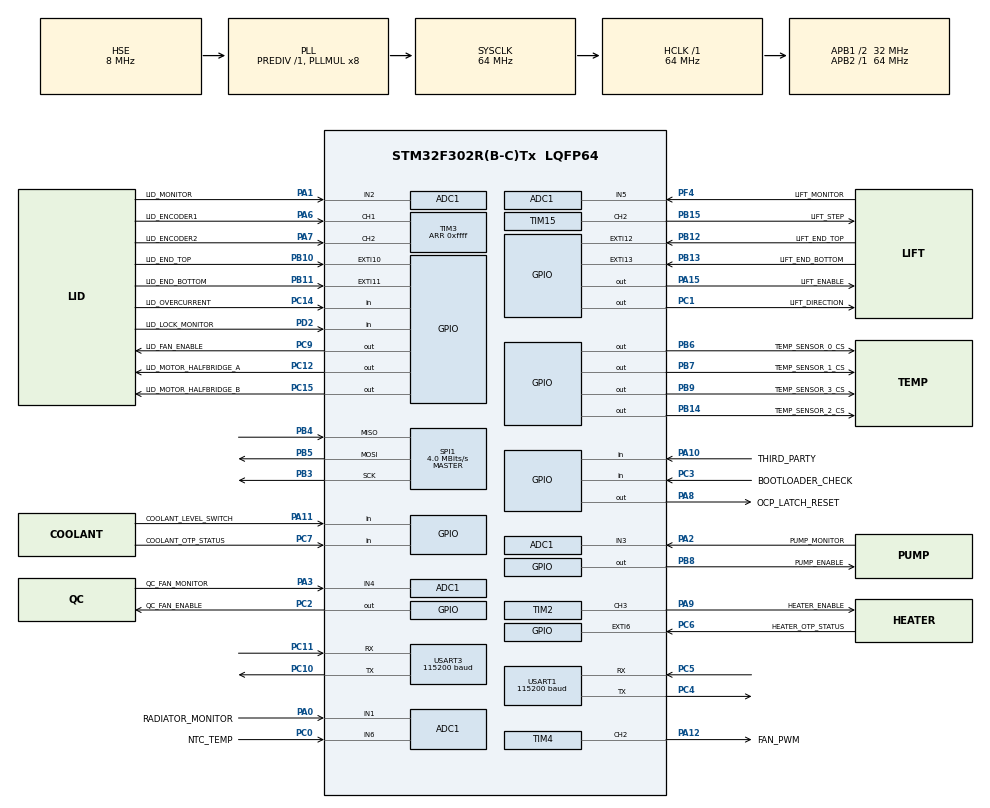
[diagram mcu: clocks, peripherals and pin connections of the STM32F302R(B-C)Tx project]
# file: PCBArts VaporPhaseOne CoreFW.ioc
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ADC1.Channel-0\#ChannelRegularConversion=ADC_CHANNEL_1
ADC1.Channel-1\#ChannelRegularConversion=ADC_CHANNEL_2
ADC1.Channel-2\#ChannelRegularConversion=ADC_CHANNEL_3
ADC1.Channel-3\#ChannelRegularConversion=ADC_CHANNEL_4
ADC1.Channel-4\#ChannelRegularConversion=ADC_CHANNEL_5
ADC1.Channel-5\#ChannelRegularConversion=ADC_CHANNEL_6
ADC1.ContinuousConvMode=ENABLE
ADC1.DMAContinuousRequests=ENABLE
ADC1.NbrOfConversion=6
ADC1.NbrOfConversionFlag=1
ADC1.Offset-0\#ChannelRegularConversion=0
ADC1.Offset-1\#ChannelRegularConversion=0
ADC1.Offset-2\#ChannelRegularConversion=0
ADC1.Offset-3\#ChannelRegularConversion=0
ADC1.Offset-4\#ChannelRegularConversion=0
ADC1.Offset-5\#ChannelRegularConversion=0
ADC1.OffsetNumber-0\#ChannelRegularConversion=ADC_OFFSET_NONE
ADC1.OffsetNumber-1\#ChannelRegularConversion=ADC_OFFSET_NONE
ADC1.OffsetNumber-2\#ChannelRegularConversion=ADC_OFFSET_NONE
ADC1.OffsetNumber-3\#ChannelRegularConversion=ADC_OFFSET_NONE
ADC1.OffsetNumber-4\#ChannelRegularConversion=ADC_OFFSET_NONE
ADC1.OffsetNumber-5\#ChannelRegularConversion=ADC_OFFSET_NONE
ADC1.Rank-0\#ChannelRegularConversion=1
ADC1.Rank-1\#ChannelRegularConversion=2
ADC1.Rank-2\#ChannelRegularConversion=3
ADC1.Rank-3\#ChannelRegularConversion=4
ADC1.Rank-4\#ChannelRegularConversion=5
ADC1.Rank-5\#ChannelRegularConversion=6
ADC1.SamplingTime-0\#ChannelRegularConversion=ADC_SAMPLETIME_601CYCLES_5
ADC1.SamplingTime-1\#ChannelRegularConversion=ADC_SAMPLETIME_601CYCLES_5
ADC1.SamplingTime-2\#ChannelRegularConversion=ADC_SAMPLETIME_601CYCLES_5
ADC1.SamplingTime-3\#ChannelRegularConversion=ADC_SAMPLETIME_601CYCLES_5
ADC1.SamplingTime-4\#ChannelRegularConversion=ADC_SAMPLETIME_601CYCLES_5
ADC1.SamplingTime-5\#ChannelRegularConversion=ADC_SAMPLETIME_601CYCLES_5
ADC1.SamplingTimeOPAMP-1\#ChannelRegularConversion=ADC_SAMPLETIME_61CYCLES_5
ADC1.SamplingTimeOPAMP-2\#ChannelRegularConversion=ADC_SAMPLETIME_61CYCLES_5
ADC1.SamplingTimeOPAMP-3\#ChannelRegularConversion=ADC_SAMPLETIME_61CYCLES_5
ADC1.SamplingTimeOPAMP-4\#ChannelRegularConversion=ADC_SAMPLETIME_61CYCLES_5
ADC1.SamplingTimeOPAMP-5\#ChannelRegularConversion=ADC_SAMPLETIME_61CYCLES_5
ADC1.master=1
Dma.ADC1.4.Direction=DMA_PERIPH_TO_MEMORY
Dma.ADC1.4.Instance=DMA1_Channel1
Dma.ADC1.4.MemDataAlignment=DMA_MDATAALIGN_WORD
Dma.ADC1.4.MemInc=DMA_MINC_ENABLE
Dma.ADC1.4.Mode=DMA_CIRCULAR
Dma.ADC1.4.PeriphDataAlignment=DMA_PDATAALIGN_HALFWORD
Dma.ADC1.4.PeriphInc=DMA_PINC_DISABLE
Dma.ADC1.4.Priority=DMA_PRIORITY_LOW
Dma.Request0=SPI1_RX
Dma.Request1=SPI1_TX
Dma.Request2=USART1_RX
Dma.Request3=USART1_TX
Dma.Request4=ADC1
Dma.SPI1_RX.0.Direction=DMA_PERIPH_TO_MEMORY
Dma.SPI1_RX.0.Instance=DMA1_Channel2
Dma.SPI1_RX.0.MemDataAlignment=DMA_MDATAALIGN_BYTE
Dma.SPI1_RX.0.MemInc=DMA_MINC_ENABLE
Dma.SPI1_RX.0.Mode=DMA_NORMAL
Dma.SPI1_RX.0.PeriphDataAlignment=DMA_PDATAALIGN_BYTE
Dma.SPI1_RX.0.PeriphInc=DMA_PINC_DISABLE
Dma.SPI1_RX.0.Priority=DMA_PRIORITY_HIGH
Dma.SPI1_TX.1.Direction=DMA_MEMORY_TO_PERIPH
Dma.SPI1_TX.1.Instance=DMA1_Channel3
Dma.SPI1_TX.1.MemDataAlignment=DMA_MDATAALIGN_BYTE
Dma.SPI1_TX.1.MemInc=DMA_MINC_ENABLE
Dma.SPI1_TX.1.Mode=DMA_NORMAL
Dma.SPI1_TX.1.PeriphDataAlignment=DMA_PDATAALIGN_BYTE
Dma.SPI1_TX.1.PeriphInc=DMA_PINC_DISABLE
Dma.SPI1_TX.1.Priority=DMA_PRIORITY_LOW
Dma.USART1_RX.2.Direction=DMA_PERIPH_TO_MEMORY
Dma.USART1_RX.2.Instance=DMA1_Channel5
Dma.USART1_RX.2.MemDataAlignment=DMA_MDATAALIGN_BYTE
Dma.USART1_RX.2.MemInc=DMA_MINC_ENABLE
Dma.USART1_RX.2.Mode=DMA_CIRCULAR
Dma.USART1_RX.2.PeriphDataAlignment=DMA_PDATAALIGN_BYTE
Dma.USART1_RX.2.PeriphInc=DMA_PINC_DISABLE
Dma.USART1_RX.2.Priority=DMA_PRIORITY_HIGH
Dma.USART1_TX.3.Direction=DMA_MEMORY_TO_PERIPH
Dma.USART1_TX.3.Instance=DMA1_Channel4
Dma.USART1_TX.3.MemDataAlignment=DMA_MDATAALIGN_BYTE
Dma.USART1_TX.3.MemInc=DMA_MINC_ENABLE
Dma.USART1_TX.3.Mode=DMA_NORMAL
Dma.USART1_TX.3.PeriphDataAlignment=DMA_PDATAALIGN_BYTE
Dma.USART1_TX.3.PeriphInc=DMA_PINC_DISABLE
Dma.USART1_TX.3.Priority=DMA_PRIORITY_LOW
Mcu.Family=STM32F3
Mcu.Name=STM32F302R(B-C)Tx
Mcu.Package=LQFP64
NVIC.DMA1_Channel2_IRQn=true\:2\:0\:true\:false\:true\:false\:true\:true
NVIC.DMA1_Channel3_IRQn=true\:2\:0\:true\:false\:true\:false\:true\:true
NVIC.DMA1_Channel4_IRQn=true\:2\:0\:true\:false\:true\:false\:true\:true
NVIC.DMA1_Channel5_IRQn=true\:2\:0\:true\:false\:true\:false\:true\:true
NVIC.EXTI15_10_IRQn=true\:3\:0\:true\:false\:true\:true\:true\:true
NVIC.EXTI9_5_IRQn=true\:2\:0\:true\:false\:true\:true\:true\:true
NVIC.PriorityGroup=NVIC_PRIORITYGROUP_3
NVIC.USART1_IRQn=true\:3\:0\:true\:false\:true\:true\:true\:true
NVIC.USART3_IRQn=true\:3\:0\:true\:false\:true\:true\:false\:true
PA0.GPIO_Label=RADIATOR_MONITOR
PA0.Mode=IN1-Single-Ended
PA0.Signal=ADC1_IN1
PA1.GPIO_Label=LID_MONITOR
PA1.Mode=IN2-Single-Ended
PA1.Signal=ADC1_IN2
PA10.GPIO_Label=THIRD_PARTY
PA10.Signal=GPIO_Input
PA11.GPIO_Label=COOLANT_LEVEL_SWITCH
PA11.Signal=GPIO_Input
PA12.GPIO_Label=FAN_PWM
PA12.Signal=S_TIM4_CH2
PA13.Mode=Serial_Wire
PA13.Signal=SYS_JTMS-SWDIO
PA14.Mode=Serial_Wire
PA14.Signal=SYS_JTCK-SWCLK
PA15.GPIO_Label=LIFT_ENABLE
PA15.Signal=GPIO_Output
PA2.GPIO_Label=PUMP_MONITOR
PA2.Mode=IN3-Single-Ended
PA2.Signal=ADC1_IN3
PA3.GPIO_Label=QC_FAN_MONITOR
PA3.Mode=IN4-Single-Ended
PA3.Signal=ADC1_IN4
PA6.GPIO_Label=LID_ENCODER1
PA6.GPIO_PuPd=GPIO_NOPULL
PA6.Signal=S_TIM3_CH1
PA7.GPIO_Label=LID_ENCODER2 
PA7.GPIO_PuPd=GPIO_NOPULL
PA7.Signal=S_TIM3_CH2
PA8.GPIO_Label=OCP_LATCH_RESET
PA8.PinState=GPIO_PIN_SET
PA8.Signal=GPIO_Output
PA9.GPIO_Label=HEATER_ENABLE
PA9.Signal=S_TIM2_CH3
PB10.GPIO_Label=LID_END_TOP
PB10.GPIO_ModeDefaultEXTI=GPIO_MODE_IT_RISING
PB10.GPIO_PuPd=GPIO_NOPULL
PB10.Signal=GPXTI10
PB11.GPIO_Label=LID_END_BOTTOM
PB11.GPIO_ModeDefaultEXTI=GPIO_MODE_IT_RISING
PB11.GPIO_PuPd=GPIO_NOPULL
PB11.Signal=GPXTI11
PB12.GPIO_Label=LIFT_END_TOP
PB12.GPIO_ModeDefaultEXTI=GPIO_MODE_IT_RISING
PB12.GPIO_PuPd=GPIO_NOPULL
PB12.Signal=GPXTI12
PB13.GPIO_Label=LIFT_END_BOTTOM
PB13.GPIO_ModeDefaultEXTI=GPIO_MODE_IT_RISING
PB13.GPIO_PuPd=GPIO_NOPULL
PB13.Signal=GPXTI13
PB14.GPIO_Label=TEMP_SENSOR_2_CS
PB14.PinState=GPIO_PIN_SET
PB14.Signal=GPIO_Output
PB15.GPIO_Label=LIFT_STEP
PB15.Signal=S_TIM15_CH2
PB3.Mode=Full_Duplex_Master
PB3.Signal=SPI1_SCK
PB4.Mode=Full_Duplex_Master
PB4.Signal=SPI1_MISO
PB5.Mode=Full_Duplex_Master
PB5.Signal=SPI1_MOSI
PB6.GPIO_Label=TEMP_SENSOR_0_CS
PB6.PinState=GPIO_PIN_SET
PB6.Signal=GPIO_Output
PB7.GPIO_Label=TEMP_SENSOR_1_CS
PB7.PinState=GPIO_PIN_SET
PB7.Signal=GPIO_Output
PB8.GPIO_Label=PUMP_ENABLE
PB8.Signal=GPIO_Output
PB9.GPIO_Label=TEMP_SENSOR_3_CS
PB9.PinState=GPIO_PIN_SET
PB9.Signal=GPIO_Output
PC0.GPIO_Label=NTC_TEMP
PC0.Signal=ADCx_IN6
PC1.GPIO_Label=LIFT_DIRECTION
PC1.Signal=GPIO_Output
PC10.GPIO_PuPd=GPIO_PULLUP
PC10.Mode=Asynchronous
PC10.Signal=USART3_TX
PC11.GPIO_PuPd=GPIO_PULLUP
PC11.Mode=Asynchronous
PC11.Signal=USART3_RX
PC12.GPIO_Label=LID_MOTOR_HALFBRIDGE_A
PC12.Signal=GPIO_Output
PC14-OSC32_IN.GPIO_Label=LID_OVERCURRENT
PC14-OSC32_IN.Signal=GPIO_Input
PC15-OSC32_OUT.GPIO_Label=LID_MOTOR_HALFBRIDGE_B
PC15-OSC32_OUT.Signal=GPIO_Output
PC2.GPIO_Label=QC_FAN_ENABLE
PC2.Signal=GPIO_Output
PC3.GPIO_Label=BOOTLOADER_CHECK
PC3.Signal=GPIO_Input
PC4.GPIO_PuPd=GPIO_PULLUP
PC4.Mode=Asynchronous
PC4.Signal=USART1_TX
PC5.GPIO_PuPd=GPIO_PULLUP
PC5.Mode=Asynchronous
PC5.Signal=USART1_RX
PC6.GPIO_Label=HEATER_OTP_STATUS
PC6.GPIO_ModeDefaultEXTI=GPIO_MODE_IT_RISING
PC6.Signal=GPXTI6
PC7.GPIO_Label=COOLANT_OTP_STATUS
PC7.Signal=GPIO_Input
PC9.GPIO_Label=LID_FAN_ENABLE
PC9.Signal=GPIO_Output
PD2.GPIO_Label=LID_LOCK_MONITOR
PD2.Signal=GPIO_Input
PF0-OSC_IN.Mode=HSE-External-Oscillator
PF0-OSC_IN.Signal=RCC_OSC_IN
PF1-OSC_OUT.Mode=HSE-External-Oscillator
PF1-OSC_OUT.Signal=RCC_OSC_OUT
PF4.GPIO_Label=LIFT_MONITOR
PF4.Mode=IN5-Single-Ended
PF4.Signal=ADC1_IN5
ProjectManager.HeapSize=0x200
ProjectManager.StackSize=0x400
ProjectManager.TargetToolchain=STM32CubeIDE
RCC.ADC12PRES=RCC_ADC12PLLCLK_DIV256
RCC.AHBFreq_Value=64000000
RCC.APB1CLKDivider=RCC_HCLK_DIV2
RCC.APB1Freq_Value=32000000
RCC.APB1TimFreq_Value=64000000
RCC.APB2Freq_Value=64000000
RCC.APB2TimFreq_Value=64000000
RCC.CortexFreq_Value=64000000
RCC.HCLKFreq_Value=64000000
RCC.HSE_VALUE=8000000
RCC.HSI_VALUE=8000000
RCC.LSE_VALUE=32768
RCC.PLLMUL=RCC_PLL_MUL8
RCC.PLLSourceVirtual=RCC_PLLSOURCE_HSE
RCC.SYSCLKFreq_VALUE=64000000
RCC.SYSCLKSourceVirtual=RCC_SYSCLKSOURCE_PLLCLK
RCC.USBFreq_Value=64000000
SH.ADCx_IN6.0=ADC1_IN6,IN6-Single-Ended
SH.S_TIM15_CH2.0=TIM15_CH2,PWM Generation2 CH2
SH.S_TIM2_CH3.0=TIM2_CH3,PWM Generation3 CH3
SH.S_TIM3_CH1.0=TIM3_CH1,Encoder_Interface
SH.S_TIM3_CH2.0=TIM3_CH2,Encoder_Interface
SH.S_TIM4_CH2.0=TIM4_CH2,PWM Generation2 CH2
SPI1.BaudRatePrescaler=SPI_BAUDRATEPRESCALER_16
SPI1.CLKPhase=SPI_PHASE_2EDGE
SPI1.CalculateBaudRate=4.0 MBits/s
SPI1.DataSize=SPI_DATASIZE_8BIT
SPI1.Direction=SPI_DIRECTION_2LINES
SPI1.Mode=SPI_MODE_MASTER
SPI1.VirtualType=VM_MASTER
TIM1.TIM_MasterOutputTrigger=TIM_TRGO_UPDATE
TIM15.Channel-PWM\ Generation2\ CH2=TIM_CHANNEL_2
TIM15.OCMode_PWM-PWM\ Generation2\ CH2=TIM_OCMODE_PWM1
TIM15.OCPolarity_2=TIM_OCPOLARITY_LOW
TIM15.Period=0
TIM15.Prescaler=31
TIM15.Pulse-PWM\ Generation2\ CH2=0
TIM15.TIM_MasterOutputTrigger=TIM_TRGO_UPDATE
TIM2.Channel-PWM\ Generation3\ CH3=TIM_CHANNEL_3
TIM2.OCMode_PWM-PWM\ Generation3\ CH3=TIM_OCMODE_PWM2
TIM2.Period=999
TIM2.Prescaler=63
TIM2.Pulse-PWM\ Generation3\ CH3=500
TIM3.Period=0xffff
TIM4.Channel-PWM\ Generation2\ CH2=TIM_CHANNEL_2
TIM4.Period=2559
USART1.BaudRate=115200
USART1.VirtualMode-Asynchronous=VM_ASYNC
USART3.BaudRate=115200
USART3.VirtualMode-Asynchronous=VM_ASYNC
VP_CRC_VS_CRC.Mode=CRC_Activate
VP_TIM1_VS_ClockSourceITR.Mode=TriggerSource_ITR0
VP_TIM1_VS_ControllerModeClock.Mode=Clock Mode
VP_TIM2_VS_ClockSourceINT.Mode=Internal
VP_TIM4_VS_ClockSourceINT.Mode=Internal
board=custom

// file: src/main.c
/* USER CODE BEGIN Header */
/*
 * * * * * * * * * * * * * * * * * * * * * * * * * * * * * * * * * * * * *
 *
 * Copyright (c) 2021 - PCB Arts GmbH
 *
 *
 * This program is free software: you can redistribute it and/or modify
 * it under the terms of the GNU General Public License as published by
 * the Free Software Foundation, either version 3 of the License, or
 * (at your option) any later version.
 *
 * You should have received a copy of the GNU General Public License
 * along with this program. If not, see <https://www.gnu.org/licenses/>.
 *
 * * * * * * * * * * * * * * * * * * * * * * * * * * * * * * * * * * * * *
 */
/* USER CODE END Header */
#include "main.h"

/* USER CODE BEGIN Includes */

#include "main/init.h"
#include "main/loop.h"

#include "peripherals/wwdg.h"

#include "log.h"
#include "version.h"

#include <stdbool.h>

/* USER CODE END Includes */

ADC_HandleTypeDef hadc1;
DMA_HandleTypeDef hdma_adc1;

CRC_HandleTypeDef hcrc;

SPI_HandleTypeDef hspi1;
DMA_HandleTypeDef hdma_spi1_rx;
DMA_HandleTypeDef hdma_spi1_tx;

TIM_HandleTypeDef htim1;
TIM_HandleTypeDef htim2;
TIM_HandleTypeDef htim3;
TIM_HandleTypeDef htim4;
TIM_HandleTypeDef htim15;

UART_HandleTypeDef huart1;
UART_HandleTypeDef huart3;
DMA_HandleTypeDef hdma_usart1_rx;
DMA_HandleTypeDef hdma_usart1_tx;

void SystemClock_Config(void);
static void MX_GPIO_Init(void);
static void MX_DMA_Init(void);
static void MX_ADC1_Init(void);
static void MX_SPI1_Init(void);
static void MX_TIM1_Init(void);
static void MX_TIM2_Init(void);
static void MX_TIM3_Init(void);
static void MX_TIM15_Init(void);
static void MX_USART1_UART_Init(void);
static void MX_USART3_UART_Init(void);
static void MX_CRC_Init(void);
static void MX_TIM4_Init(void);

int main(void)
{

  /* MCU Configuration--------------------------------------------------------*/

  /* Reset of all peripherals, Initializes the Flash interface and the Systick. */
  HAL_Init();

  /* Configure the system clock */
  SystemClock_Config();

  /* Initialize all configured peripherals */
  MX_GPIO_Init();
  MX_DMA_Init();
  MX_ADC1_Init();
  MX_SPI1_Init();
  MX_TIM1_Init();
  MX_TIM2_Init();
  MX_TIM3_Init();
  MX_TIM15_Init();
  MX_USART1_UART_Init();
  MX_USART3_UART_Init();
  MX_CRC_Init();
  MX_TIM4_Init();
  /* USER CODE BEGIN 2 */

  //test out delay maybe it stabilizes some signals?
  HAL_Delay(100);

  init_modules();
  /* USER CODE END 2 */

  /* Infinite loop */
  /* USER CODE BEGIN WHILE */
  wwdg_init();
  while (1) {
	main_loop();

    /* USER CODE END WHILE */

  }
}

void SystemClock_Config(void)
{
  RCC_OscInitTypeDef RCC_OscInitStruct = {0};
  RCC_ClkInitTypeDef RCC_ClkInitStruct = {0};
  RCC_PeriphCLKInitTypeDef PeriphClkInit = {0};

  /** Initializes the RCC Oscillators according to the specified parameters
  * in the RCC_OscInitTypeDef structure.
  */
  RCC_OscInitStruct.OscillatorType = RCC_OSCILLATORTYPE_HSE;
  RCC_OscInitStruct.HSEState = RCC_HSE_ON;
  RCC_OscInitStruct.HSEPredivValue = RCC_HSE_PREDIV_DIV1;
  RCC_OscInitStruct.HSIState = RCC_HSI_ON;
  RCC_OscInitStruct.PLL.PLLState = RCC_PLL_ON;
  RCC_OscInitStruct.PLL.PLLSource = RCC_PLLSOURCE_HSE;
  RCC_OscInitStruct.PLL.PLLMUL = RCC_PLL_MUL8;
  if (HAL_RCC_OscConfig(&RCC_OscInitStruct) != HAL_OK)
  {
    Error_Handler();
  }
  /** Initializes the CPU, AHB and APB buses clocks
  */
  RCC_ClkInitStruct.ClockType = RCC_CLOCKTYPE_HCLK|RCC_CLOCKTYPE_SYSCLK
                              |RCC_CLOCKTYPE_PCLK1|RCC_CLOCKTYPE_PCLK2;
  RCC_ClkInitStruct.SYSCLKSource = RCC_SYSCLKSOURCE_PLLCLK;
  RCC_ClkInitStruct.AHBCLKDivider = RCC_SYSCLK_DIV1;
  RCC_ClkInitStruct.APB1CLKDivider = RCC_HCLK_DIV2;
  RCC_ClkInitStruct.APB2CLKDivider = RCC_HCLK_DIV1;

  if (HAL_RCC_ClockConfig(&RCC_ClkInitStruct, FLASH_LATENCY_2) != HAL_OK)
  {
    Error_Handler();
  }
  PeriphClkInit.PeriphClockSelection = RCC_PERIPHCLK_USART1|RCC_PERIPHCLK_USART3
                              |RCC_PERIPHCLK_TIM1|RCC_PERIPHCLK_ADC12;
  PeriphClkInit.Usart1ClockSelection = RCC_USART1CLKSOURCE_PCLK2;
  PeriphClkInit.Usart3ClockSelection = RCC_USART3CLKSOURCE_PCLK1;
  PeriphClkInit.Adc12ClockSelection = RCC_ADC12PLLCLK_DIV256;
  PeriphClkInit.Tim1ClockSelection = RCC_TIM1CLK_HCLK;
  if (HAL_RCCEx_PeriphCLKConfig(&PeriphClkInit) != HAL_OK)
  {
    Error_Handler();
  }
}

static void MX_ADC1_Init(void)
{

  ADC_MultiModeTypeDef multimode = {0};
  ADC_ChannelConfTypeDef sConfig = {0};

  /** Common config
  */
  hadc1.Instance = ADC1;
  hadc1.Init.ClockPrescaler = ADC_CLOCK_ASYNC_DIV1;
  hadc1.Init.Resolution = ADC_RESOLUTION_12B;
  hadc1.Init.ScanConvMode = ADC_SCAN_ENABLE;
  hadc1.Init.ContinuousConvMode = ENABLE;
  hadc1.Init.DiscontinuousConvMode = DISABLE;
  hadc1.Init.ExternalTrigConvEdge = ADC_EXTERNALTRIGCONVEDGE_NONE;
  hadc1.Init.ExternalTrigConv = ADC_SOFTWARE_START;
  hadc1.Init.DataAlign = ADC_DATAALIGN_RIGHT;
  hadc1.Init.NbrOfConversion = 6;
  hadc1.Init.DMAContinuousRequests = ENABLE;
  hadc1.Init.EOCSelection = ADC_EOC_SINGLE_CONV;
  hadc1.Init.LowPowerAutoWait = DISABLE;
  hadc1.Init.Overrun = ADC_OVR_DATA_OVERWRITTEN;
  if (HAL_ADC_Init(&hadc1) != HAL_OK)
  {
    Error_Handler();
  }
  /** Configure the ADC multi-mode
  */
  multimode.Mode = ADC_MODE_INDEPENDENT;
  if (HAL_ADCEx_MultiModeConfigChannel(&hadc1, &multimode) != HAL_OK)
  {
    Error_Handler();
  }
  /** Configure Regular Channel
  */
  sConfig.Channel = ADC_CHANNEL_1;
  sConfig.Rank = ADC_REGULAR_RANK_1;
  sConfig.SingleDiff = ADC_SINGLE_ENDED;
  sConfig.SamplingTime = ADC_SAMPLETIME_601CYCLES_5;
  sConfig.OffsetNumber = ADC_OFFSET_NONE;
  sConfig.Offset = 0;
  if (HAL_ADC_ConfigChannel(&hadc1, &sConfig) != HAL_OK)
  {
    Error_Handler();
  }
  /** Configure Regular Channel
  */
  sConfig.Channel = ADC_CHANNEL_2;
  sConfig.Rank = ADC_REGULAR_RANK_2;
  if (HAL_ADC_ConfigChannel(&hadc1, &sConfig) != HAL_OK)
  {
    Error_Handler();
  }
  /** Configure Regular Channel
  */
  sConfig.Channel = ADC_CHANNEL_3;
  sConfig.Rank = ADC_REGULAR_RANK_3;
  if (HAL_ADC_ConfigChannel(&hadc1, &sConfig) != HAL_OK)
  {
    Error_Handler();
  }
  /** Configure Regular Channel
  */
  sConfig.Channel = ADC_CHANNEL_4;
  sConfig.Rank = ADC_REGULAR_RANK_4;
  if (HAL_ADC_ConfigChannel(&hadc1, &sConfig) != HAL_OK)
  {
    Error_Handler();
  }
  /** Configure Regular Channel
  */
  sConfig.Channel = ADC_CHANNEL_5;
  sConfig.Rank = ADC_REGULAR_RANK_5;
  if (HAL_ADC_ConfigChannel(&hadc1, &sConfig) != HAL_OK)
  {
    Error_Handler();
  }
  /** Configure Regular Channel
  */
  sConfig.Channel = ADC_CHANNEL_6;
  sConfig.Rank = ADC_REGULAR_RANK_6;
  if (HAL_ADC_ConfigChannel(&hadc1, &sConfig) != HAL_OK)
  {
    Error_Handler();
  }

}

static void MX_CRC_Init(void)
{

  hcrc.Instance = CRC;
  hcrc.Init.DefaultPolynomialUse = DEFAULT_POLYNOMIAL_ENABLE;
  hcrc.Init.DefaultInitValueUse = DEFAULT_INIT_VALUE_ENABLE;
  hcrc.Init.InputDataInversionMode = CRC_INPUTDATA_INVERSION_NONE;
  hcrc.Init.OutputDataInversionMode = CRC_OUTPUTDATA_INVERSION_DISABLE;
  hcrc.InputDataFormat = CRC_INPUTDATA_FORMAT_BYTES;
  if (HAL_CRC_Init(&hcrc) != HAL_OK)
  {
    Error_Handler();
  }

}

static void MX_SPI1_Init(void)
{

  /* SPI1 parameter configuration*/
  hspi1.Instance = SPI1;
  hspi1.Init.Mode = SPI_MODE_MASTER;
  hspi1.Init.Direction = SPI_DIRECTION_2LINES;
  hspi1.Init.DataSize = SPI_DATASIZE_8BIT;
  hspi1.Init.CLKPolarity = SPI_POLARITY_LOW;
  hspi1.Init.CLKPhase = SPI_PHASE_2EDGE;
  hspi1.Init.NSS = SPI_NSS_SOFT;
  hspi1.Init.BaudRatePrescaler = SPI_BAUDRATEPRESCALER_16;
  hspi1.Init.FirstBit = SPI_FIRSTBIT_MSB;
  hspi1.Init.TIMode = SPI_TIMODE_DISABLE;
  hspi1.Init.CRCCalculation = SPI_CRCCALCULATION_DISABLE;
  hspi1.Init.CRCPolynomial = 7;
  hspi1.Init.CRCLength = SPI_CRC_LENGTH_DATASIZE;
  hspi1.Init.NSSPMode = SPI_NSS_PULSE_DISABLE;
  if (HAL_SPI_Init(&hspi1) != HAL_OK)
  {
    Error_Handler();
  }

}

static void MX_TIM1_Init(void)
{

  TIM_SlaveConfigTypeDef sSlaveConfig = {0};
  TIM_MasterConfigTypeDef sMasterConfig = {0};

  htim1.Instance = TIM1;
  htim1.Init.Prescaler = 0;
  htim1.Init.CounterMode = TIM_COUNTERMODE_UP;
  htim1.Init.Period = 65535;
  htim1.Init.ClockDivision = TIM_CLOCKDIVISION_DIV1;
  htim1.Init.RepetitionCounter = 0;
  htim1.Init.AutoReloadPreload = TIM_AUTORELOAD_PRELOAD_DISABLE;
  if (HAL_TIM_Base_Init(&htim1) != HAL_OK)
  {
    Error_Handler();
  }
  sSlaveConfig.SlaveMode = TIM_SLAVEMODE_EXTERNAL1;
  sSlaveConfig.InputTrigger = TIM_TS_ITR0;
  if (HAL_TIM_SlaveConfigSynchro(&htim1, &sSlaveConfig) != HAL_OK)
  {
    Error_Handler();
  }
  sMasterConfig.MasterOutputTrigger = TIM_TRGO_UPDATE;
  sMasterConfig.MasterOutputTrigger2 = TIM_TRGO2_RESET;
  sMasterConfig.MasterSlaveMode = TIM_MASTERSLAVEMODE_DISABLE;
  if (HAL_TIMEx_MasterConfigSynchronization(&htim1, &sMasterConfig) != HAL_OK)
  {
    Error_Handler();
  }

}

static void MX_TIM2_Init(void)
{

  TIM_ClockConfigTypeDef sClockSourceConfig = {0};
  TIM_MasterConfigTypeDef sMasterConfig = {0};
  TIM_OC_InitTypeDef sConfigOC = {0};

  htim2.Instance = TIM2;
  htim2.Init.Prescaler = 63;
  htim2.Init.CounterMode = TIM_COUNTERMODE_UP;
  htim2.Init.Period = 999;
  htim2.Init.ClockDivision = TIM_CLOCKDIVISION_DIV1;
  htim2.Init.AutoReloadPreload = TIM_AUTORELOAD_PRELOAD_DISABLE;
  if (HAL_TIM_Base_Init(&htim2) != HAL_OK)
  {
    Error_Handler();
  }
  sClockSourceConfig.ClockSource = TIM_CLOCKSOURCE_INTERNAL;
  if (HAL_TIM_ConfigClockSource(&htim2, &sClockSourceConfig) != HAL_OK)
  {
    Error_Handler();
  }
  if (HAL_TIM_PWM_Init(&htim2) != HAL_OK)
  {
    Error_Handler();
  }
  sMasterConfig.MasterOutputTrigger = TIM_TRGO_RESET;
  sMasterConfig.MasterSlaveMode = TIM_MASTERSLAVEMODE_DISABLE;
  if (HAL_TIMEx_MasterConfigSynchronization(&htim2, &sMasterConfig) != HAL_OK)
  {
    Error_Handler();
  }
  sConfigOC.OCMode = TIM_OCMODE_PWM2;
  sConfigOC.Pulse = 500;
  sConfigOC.OCPolarity = TIM_OCPOLARITY_HIGH;
  sConfigOC.OCFastMode = TIM_OCFAST_DISABLE;
  if (HAL_TIM_PWM_ConfigChannel(&htim2, &sConfigOC, TIM_CHANNEL_3) != HAL_OK)
  {
    Error_Handler();
  }
  HAL_TIM_MspPostInit(&htim2);

}

static void MX_TIM3_Init(void)
{

  TIM_Encoder_InitTypeDef sConfig = {0};
  TIM_MasterConfigTypeDef sMasterConfig = {0};

  htim3.Instance = TIM3;
  htim3.Init.Prescaler = 0;
  htim3.Init.CounterMode = TIM_COUNTERMODE_UP;
  htim3.Init.Period = 0xffff;
  htim3.Init.ClockDivision = TIM_CLOCKDIVISION_DIV1;
  htim3.Init.AutoReloadPreload = TIM_AUTORELOAD_PRELOAD_DISABLE;
  sConfig.EncoderMode = TIM_ENCODERMODE_TI1;
  sConfig.IC1Polarity = TIM_ICPOLARITY_RISING;
  sConfig.IC1Selection = TIM_ICSELECTION_DIRECTTI;
  sConfig.IC1Prescaler = TIM_ICPSC_DIV1;
  sConfig.IC1Filter = 0;
  sConfig.IC2Polarity = TIM_ICPOLARITY_RISING;
  sConfig.IC2Selection = TIM_ICSELECTION_DIRECTTI;
  sConfig.IC2Prescaler = TIM_ICPSC_DIV1;
  sConfig.IC2Filter = 0;
  if (HAL_TIM_Encoder_Init(&htim3, &sConfig) != HAL_OK)
  {
    Error_Handler();
  }
  sMasterConfig.MasterOutputTrigger = TIM_TRGO_RESET;
  sMasterConfig.MasterSlaveMode = TIM_MASTERSLAVEMODE_DISABLE;
  if (HAL_TIMEx_MasterConfigSynchronization(&htim3, &sMasterConfig) != HAL_OK)
  {
    Error_Handler();
  }

}

static void MX_TIM4_Init(void)
{

  TIM_ClockConfigTypeDef sClockSourceConfig = {0};
  TIM_MasterConfigTypeDef sMasterConfig = {0};
  TIM_OC_InitTypeDef sConfigOC = {0};

  htim4.Instance = TIM4;
  htim4.Init.Prescaler = 0;
  htim4.Init.CounterMode = TIM_COUNTERMODE_UP;
  htim4.Init.Period = 2559;
  htim4.Init.ClockDivision = TIM_CLOCKDIVISION_DIV1;
  htim4.Init.AutoReloadPreload = TIM_AUTORELOAD_PRELOAD_DISABLE;
  if (HAL_TIM_Base_Init(&htim4) != HAL_OK)
  {
    Error_Handler();
  }
  sClockSourceConfig.ClockSource = TIM_CLOCKSOURCE_INTERNAL;
  if (HAL_TIM_ConfigClockSource(&htim4, &sClockSourceConfig) != HAL_OK)
  {
    Error_Handler();
  }
  if (HAL_TIM_PWM_Init(&htim4) != HAL_OK)
  {
    Error_Handler();
  }
  sMasterConfig.MasterOutputTrigger = TIM_TRGO_RESET;
  sMasterConfig.MasterSlaveMode = TIM_MASTERSLAVEMODE_DISABLE;
  if (HAL_TIMEx_MasterConfigSynchronization(&htim4, &sMasterConfig) != HAL_OK)
  {
    Error_Handler();
  }
  sConfigOC.OCMode = TIM_OCMODE_PWM1;
  sConfigOC.Pulse = 0;
  sConfigOC.OCPolarity = TIM_OCPOLARITY_HIGH;
  sConfigOC.OCFastMode = TIM_OCFAST_DISABLE;
  if (HAL_TIM_PWM_ConfigChannel(&htim4, &sConfigOC, TIM_CHANNEL_2) != HAL_OK)
  {
    Error_Handler();
  }
  HAL_TIM_MspPostInit(&htim4);

}

static void MX_TIM15_Init(void)
{

  TIM_MasterConfigTypeDef sMasterConfig = {0};
  TIM_OC_InitTypeDef sConfigOC = {0};
  TIM_BreakDeadTimeConfigTypeDef sBreakDeadTimeConfig = {0};

  htim15.Instance = TIM15;
  htim15.Init.Prescaler = 31;
  htim15.Init.CounterMode = TIM_COUNTERMODE_UP;
  htim15.Init.Period = 0;
  htim15.Init.ClockDivision = TIM_CLOCKDIVISION_DIV1;
  htim15.Init.RepetitionCounter = 0;
  htim15.Init.AutoReloadPreload = TIM_AUTORELOAD_PRELOAD_DISABLE;
  if (HAL_TIM_PWM_Init(&htim15) != HAL_OK)
  {
    Error_Handler();
  }
  sMasterConfig.MasterOutputTrigger = TIM_TRGO_UPDATE;
  sMasterConfig.MasterSlaveMode = TIM_MASTERSLAVEMODE_DISABLE;
  if (HAL_TIMEx_MasterConfigSynchronization(&htim15, &sMasterConfig) != HAL_OK)
  {
    Error_Handler();
  }
  sConfigOC.OCMode = TIM_OCMODE_PWM1;
  sConfigOC.Pulse = 0;
  sConfigOC.OCPolarity = TIM_OCPOLARITY_LOW;
  sConfigOC.OCNPolarity = TIM_OCNPOLARITY_HIGH;
  sConfigOC.OCFastMode = TIM_OCFAST_DISABLE;
  sConfigOC.OCIdleState = TIM_OCIDLESTATE_RESET;
  sConfigOC.OCNIdleState = TIM_OCNIDLESTATE_RESET;
  if (HAL_TIM_PWM_ConfigChannel(&htim15, &sConfigOC, TIM_CHANNEL_2) != HAL_OK)
  {
    Error_Handler();
  }
  sBreakDeadTimeConfig.OffStateRunMode = TIM_OSSR_DISABLE;
  sBreakDeadTimeConfig.OffStateIDLEMode = TIM_OSSI_DISABLE;
  sBreakDeadTimeConfig.LockLevel = TIM_LOCKLEVEL_OFF;
  sBreakDeadTimeConfig.DeadTime = 0;
  sBreakDeadTimeConfig.BreakState = TIM_BREAK_DISABLE;
  sBreakDeadTimeConfig.BreakPolarity = TIM_BREAKPOLARITY_HIGH;
  sBreakDeadTimeConfig.BreakFilter = 0;
  sBreakDeadTimeConfig.AutomaticOutput = TIM_AUTOMATICOUTPUT_DISABLE;
  if (HAL_TIMEx_ConfigBreakDeadTime(&htim15, &sBreakDeadTimeConfig) != HAL_OK)
  {
    Error_Handler();
  }
  HAL_TIM_MspPostInit(&htim15);

}

static void MX_USART1_UART_Init(void)
{

  huart1.Instance = USART1;
  huart1.Init.BaudRate = 115200;
  huart1.Init.WordLength = UART_WORDLENGTH_8B;
  huart1.Init.StopBits = UART_STOPBITS_1;
  huart1.Init.Parity = UART_PARITY_NONE;
  huart1.Init.Mode = UART_MODE_TX_RX;
  huart1.Init.HwFlowCtl = UART_HWCONTROL_NONE;
  huart1.Init.OverSampling = UART_OVERSAMPLING_16;
  huart1.Init.OneBitSampling = UART_ONE_BIT_SAMPLE_DISABLE;
  huart1.AdvancedInit.AdvFeatureInit = UART_ADVFEATURE_NO_INIT;
  if (HAL_UART_Init(&huart1) != HAL_OK)
  {
    Error_Handler();
  }

}

static void MX_USART3_UART_Init(void)
{

  huart3.Instance = USART3;
  huart3.Init.BaudRate = 115200;
  huart3.Init.WordLength = UART_WORDLENGTH_8B;
  huart3.Init.StopBits = UART_STOPBITS_1;
  huart3.Init.Parity = UART_PARITY_NONE;
  huart3.Init.Mode = UART_MODE_TX_RX;
  huart3.Init.HwFlowCtl = UART_HWCONTROL_NONE;
  huart3.Init.OverSampling = UART_OVERSAMPLING_16;
  huart3.Init.OneBitSampling = UART_ONE_BIT_SAMPLE_DISABLE;
  huart3.AdvancedInit.AdvFeatureInit = UART_ADVFEATURE_NO_INIT;
  if (HAL_UART_Init(&huart3) != HAL_OK)
  {
    Error_Handler();
  }

}

static void MX_DMA_Init(void)
{

  /* DMA controller clock enable */
  __HAL_RCC_DMA1_CLK_ENABLE();

  /* DMA interrupt init */
  /* DMA1_Channel2_IRQn interrupt configuration */
  HAL_NVIC_SetPriority(DMA1_Channel2_IRQn, 2, 0);
  HAL_NVIC_EnableIRQ(DMA1_Channel2_IRQn);
  /* DMA1_Channel3_IRQn interrupt configuration */
  HAL_NVIC_SetPriority(DMA1_Channel3_IRQn, 2, 0);
  HAL_NVIC_EnableIRQ(DMA1_Channel3_IRQn);
  /* DMA1_Channel4_IRQn interrupt configuration */
  HAL_NVIC_SetPriority(DMA1_Channel4_IRQn, 2, 0);
  HAL_NVIC_EnableIRQ(DMA1_Channel4_IRQn);
  /* DMA1_Channel5_IRQn interrupt configuration */
  HAL_NVIC_SetPriority(DMA1_Channel5_IRQn, 2, 0);
  HAL_NVIC_EnableIRQ(DMA1_Channel5_IRQn);

}

static void MX_GPIO_Init(void)
{
  GPIO_InitTypeDef GPIO_InitStruct = {0};

  /* GPIO Ports Clock Enable */
  __HAL_RCC_GPIOC_CLK_ENABLE();
  __HAL_RCC_GPIOF_CLK_ENABLE();
  __HAL_RCC_GPIOA_CLK_ENABLE();
  __HAL_RCC_GPIOB_CLK_ENABLE();
  __HAL_RCC_GPIOD_CLK_ENABLE();

  /*Configure GPIO pin Output Level */
  HAL_GPIO_WritePin(GPIOC, LID_MOTOR_HALFBRIDGE_B_Pin|LIFT_DIRECTION_Pin|QC_FAN_ENABLE_Pin|LID_FAN_ENABLE_Pin
                          |LID_MOTOR_HALFBRIDGE_A_Pin, GPIO_PIN_RESET);

  /*Configure GPIO pin Output Level */
  HAL_GPIO_WritePin(GPIOB, TEMP_SENSOR_2_CS_Pin|TEMP_SENSOR_0_CS_Pin|TEMP_SENSOR_1_CS_Pin|TEMP_SENSOR_3_CS_Pin, GPIO_PIN_SET);

  /*Configure GPIO pin Output Level */
  HAL_GPIO_WritePin(OCP_LATCH_RESET_GPIO_Port, OCP_LATCH_RESET_Pin, GPIO_PIN_SET);

  /*Configure GPIO pin Output Level */
  HAL_GPIO_WritePin(LIFT_ENABLE_GPIO_Port, LIFT_ENABLE_Pin, GPIO_PIN_RESET);

  /*Configure GPIO pin Output Level */
  HAL_GPIO_WritePin(PUMP_ENABLE_GPIO_Port, PUMP_ENABLE_Pin, GPIO_PIN_RESET);

  /*Configure GPIO pins : LID_OVERCURRENT_Pin BOOTLOADER_CHECK_Pin COOLANT_OTP_STATUS_Pin */
  GPIO_InitStruct.Pin = LID_OVERCURRENT_Pin|BOOTLOADER_CHECK_Pin|COOLANT_OTP_STATUS_Pin;
  GPIO_InitStruct.Mode = GPIO_MODE_INPUT;
  GPIO_InitStruct.Pull = GPIO_NOPULL;
  HAL_GPIO_Init(GPIOC, &GPIO_InitStruct);

  /*Configure GPIO pins : LID_MOTOR_HALFBRIDGE_B_Pin LIFT_DIRECTION_Pin QC_FAN_ENABLE_Pin LID_FAN_ENABLE_Pin
                           LID_MOTOR_HALFBRIDGE_A_Pin */
  GPIO_InitStruct.Pin = LID_MOTOR_HALFBRIDGE_B_Pin|LIFT_DIRECTION_Pin|QC_FAN_ENABLE_Pin|LID_FAN_ENABLE_Pin
                          |LID_MOTOR_HALFBRIDGE_A_Pin;
  GPIO_InitStruct.Mode = GPIO_MODE_OUTPUT_PP;
  GPIO_InitStruct.Pull = GPIO_NOPULL;
  GPIO_InitStruct.Speed = GPIO_SPEED_FREQ_LOW;
  HAL_GPIO_Init(GPIOC, &GPIO_InitStruct);

  /*Configure GPIO pins : LID_END_TOP_Pin LID_END_BOTTOM_Pin LIFT_END_TOP_Pin LIFT_END_BOTTOM_Pin */
  GPIO_InitStruct.Pin = LID_END_TOP_Pin|LID_END_BOTTOM_Pin|LIFT_END_TOP_Pin|LIFT_END_BOTTOM_Pin;
  GPIO_InitStruct.Mode = GPIO_MODE_IT_RISING;
  GPIO_InitStruct.Pull = GPIO_NOPULL;
  HAL_GPIO_Init(GPIOB, &GPIO_InitStruct);

  /*Configure GPIO pins : TEMP_SENSOR_2_CS_Pin TEMP_SENSOR_0_CS_Pin TEMP_SENSOR_1_CS_Pin PUMP_ENABLE_Pin
                           TEMP_SENSOR_3_CS_Pin */
  GPIO_InitStruct.Pin = TEMP_SENSOR_2_CS_Pin|TEMP_SENSOR_0_CS_Pin|TEMP_SENSOR_1_CS_Pin|PUMP_ENABLE_Pin
                          |TEMP_SENSOR_3_CS_Pin;
  GPIO_InitStruct.Mode = GPIO_MODE_OUTPUT_PP;
  GPIO_InitStruct.Pull = GPIO_NOPULL;
  GPIO_InitStruct.Speed = GPIO_SPEED_FREQ_LOW;
  HAL_GPIO_Init(GPIOB, &GPIO_InitStruct);

  /*Configure GPIO pin : HEATER_OTP_STATUS_Pin */
  GPIO_InitStruct.Pin = HEATER_OTP_STATUS_Pin;
  GPIO_InitStruct.Mode = GPIO_MODE_IT_RISING;
  GPIO_InitStruct.Pull = GPIO_NOPULL;
  HAL_GPIO_Init(HEATER_OTP_STATUS_GPIO_Port, &GPIO_InitStruct);

  /*Configure GPIO pins : OCP_LATCH_RESET_Pin LIFT_ENABLE_Pin */
  GPIO_InitStruct.Pin = OCP_LATCH_RESET_Pin|LIFT_ENABLE_Pin;
  GPIO_InitStruct.Mode = GPIO_MODE_OUTPUT_PP;
  GPIO_InitStruct.Pull = GPIO_NOPULL;
  GPIO_InitStruct.Speed = GPIO_SPEED_FREQ_LOW;
  HAL_GPIO_Init(GPIOA, &GPIO_InitStruct);

  /*Configure GPIO pins : THIRD_PARTY_Pin COOLANT_LEVEL_SWITCH_Pin */
  GPIO_InitStruct.Pin = THIRD_PARTY_Pin|COOLANT_LEVEL_SWITCH_Pin;
  GPIO_InitStruct.Mode = GPIO_MODE_INPUT;
  GPIO_InitStruct.Pull = GPIO_NOPULL;
  HAL_GPIO_Init(GPIOA, &GPIO_InitStruct);

  /*Configure GPIO pin : LID_LOCK_MONITOR_Pin */
  GPIO_InitStruct.Pin = LID_LOCK_MONITOR_Pin;
  GPIO_InitStruct.Mode = GPIO_MODE_INPUT;
  GPIO_InitStruct.Pull = GPIO_NOPULL;
  HAL_GPIO_Init(LID_LOCK_MONITOR_GPIO_Port, &GPIO_InitStruct);

  /* EXTI interrupt init*/
  HAL_NVIC_SetPriority(EXTI9_5_IRQn, 2, 0);
  HAL_NVIC_EnableIRQ(EXTI9_5_IRQn);

  HAL_NVIC_SetPriority(EXTI15_10_IRQn, 3, 0);
  HAL_NVIC_EnableIRQ(EXTI15_10_IRQn);

}

void Error_Handler(void)
{
  __disable_irq();
  while (1)
  {
  }
}

/************************ (C) COPYRIGHT STMicroelectronics *****END OF FILE****/
